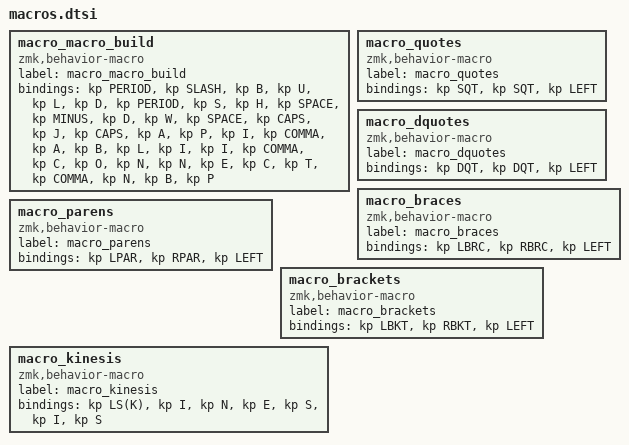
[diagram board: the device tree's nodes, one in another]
macro_macro_build: macro_macro_build{
compatible = "zmk,behavior-macro";
label = "macro_macro_build";
#binding-cells = <0>;
bindings = <&kp PERIOD>, <&kp SLASH>, <&kp B>, <&kp U>, <&kp L>, <&kp D>, <&kp PERIOD>, <&kp S>, <&kp H>, <&kp SPACE>, <&kp MINUS>, <&kp D>, <&kp W>, <&kp SPACE>, <&kp CAPS>, <&kp J>, <&kp CAPS>, <&kp A>, <&kp P>, <&kp I>, <&kp COMMA>, <&kp A>, <&kp B>, <&kp L>, <&kp I>, <&kp I>, <&kp COMMA>, <&kp C>, <&kp O>, <&kp N>, <&kp N>, <&kp E>, <&kp C>, <&kp T>, <&kp COMMA>, <&kp N>, <&kp B>, <&kp P>;
};
macro_quotes: macro_quotes{
compatible = "zmk,behavior-macro";
label = "macro_quotes";
#binding-cells = <0>;
bindings = <&kp SQT>, <&kp SQT>, <&kp LEFT>;
};
macro_dquotes: macro_dquotes{
compatible = "zmk,behavior-macro";
label = "macro_dquotes";
#binding-cells = <0>;
bindings = <&kp DQT>, <&kp DQT>, <&kp LEFT>;
};
macro_braces: macro_braces{
compatible = "zmk,behavior-macro";
label = "macro_braces";
#binding-cells = <0>;
bindings = <&kp LBRC>, <&kp RBRC>, <&kp LEFT>;
};
macro_parens: macro_parens{
compatible = "zmk,behavior-macro";
label = "macro_parens";
#binding-cells = <0>;
bindings = <&kp LPAR>, <&kp RPAR>, <&kp LEFT>;
};
macro_brackets: macro_brackets{
compatible = "zmk,behavior-macro";
label = "macro_brackets";
#binding-cells = <0>;
bindings = <&kp LBKT>, <&kp RBKT>, <&kp LEFT>;
};
macro_kinesis: macro_kinesis{
compatible = "zmk,behavior-macro";
label = "macro_kinesis";
#binding-cells = <0>;
bindings = <&kp LS(K)>, <&kp I>, <&kp N>, <&kp E>, <&kp S>, <&kp I>, <&kp S>;
};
